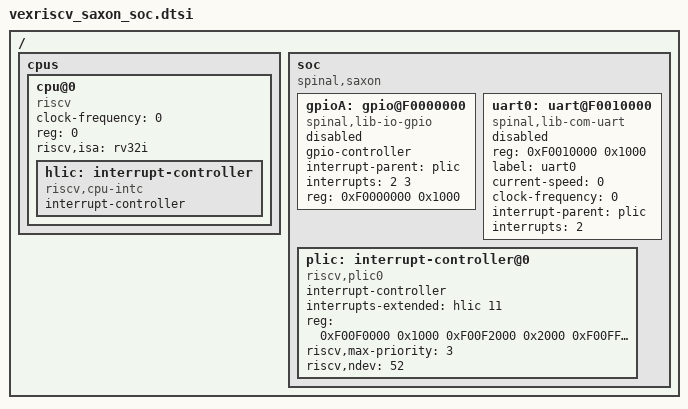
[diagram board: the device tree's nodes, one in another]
/*
 * Copyright (c) 2018 Linaro Limited
 *
 * SPDX-License-Identifier: Apache-2.0
 */

/ {
	#address-cells = <1>;
	#size-cells = <1>;

	cpus {
		#address-cells = <1>;
		#size-cells = <0>;
		cpu@0 {
			clock-frequency = <0>;
			compatible = "riscv";
			device_type = "cpu";
			reg = <0>;
			riscv,isa = "rv32i";
			hlic: interrupt-controller {
				#interrupt-cells = <1>;
				compatible = "riscv,cpu-intc";
				interrupt-controller;
			};
		};
	};

	soc {
		#address-cells = <1>;
		#size-cells = <1>;
		compatible = "spinal,saxon";
		ranges;

		gpioA: gpio@F0000000 {
			compatible = "spinal,lib-io-gpio";
			gpio-controller;
			interrupt-parent = <&plic>;
			interrupts = <2 3>;
			reg = <0xF0000000 0x1000>;
			reg-names = "control";
			status = "disabled";
			#gpio-cells = <2>;
		};
		
		uart0: uart@F0010000 {
			compatible = "spinal,lib-com-uart";
			reg = <0xF0010000 0x1000>;
			label = "uart0";
			status = "disabled";
			current-speed = <0>;
			clock-frequency = <0>;
			interrupt-parent = <&plic>;
			interrupts = <2>;
		};
		
		plic: interrupt-controller@0 {
			#interrupt-cells = <1>;
			compatible = "riscv,plic0";			
			interrupt-controller;
			interrupts-extended = <&hlic 11>;
			reg = <0xF00F0000 0x1000
			       0xF00F2000 0x2000
			       0xF00FF000 0x1000>;
			reg-names = "prio", "irq_en", "reg";
			riscv,max-priority = <3>;
			riscv,ndev = <52>;
		};
	};
};
